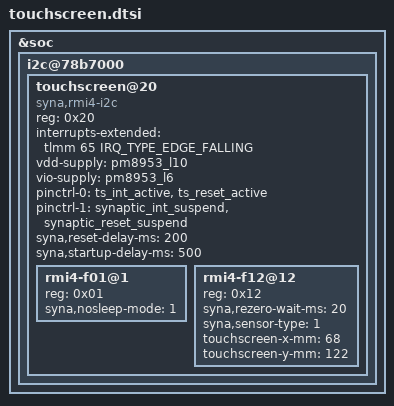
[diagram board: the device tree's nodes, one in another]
&soc { 
	i2c@78b7000 { /* BLSP1 QUP3 */
		status = "okay";

		touchscreen@20 {
			reg = <0x20>;
			compatible = "syna,rmi4-i2c";
			interrupts-extended = <&tlmm 65 IRQ_TYPE_EDGE_FALLING>;

			#address-cells = <1>;
			#size-cells = <0>;

			vdd-supply = <&pm8953_l10>;
			vio-supply = <&pm8953_l6>;

			pinctrl-names = "pmx_ts_active", "pmx_ts_suspend";
			pinctrl-0 = <&ts_int_active &ts_reset_active>;
            		pinctrl-1 = <&synaptic_int_suspend &synaptic_reset_suspend>;
			syna,reset-delay-ms = <200>;
			syna,startup-delay-ms = <500>;

			rmi4-f01@1 {
				reg = <0x01>;
				syna,nosleep-mode = <1>;
			};

			rmi4-f12@12 {
				reg = <0x12>;
				syna,rezero-wait-ms = <20>;
				syna,sensor-type = <1>;
				touchscreen-x-mm = <68>;
				touchscreen-y-mm = <122>;
			};
		};
	};
};
